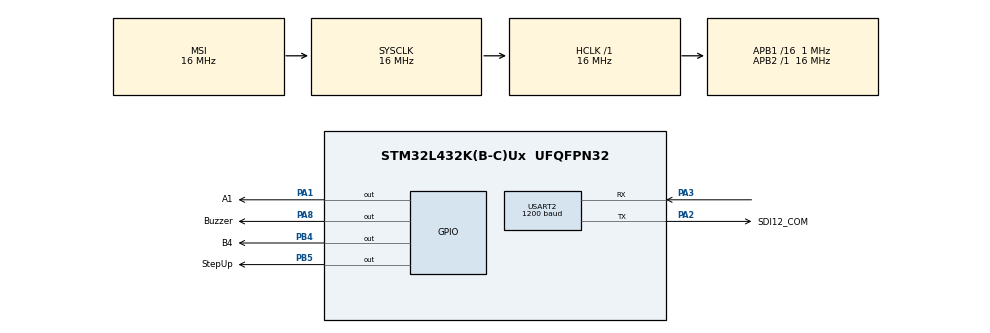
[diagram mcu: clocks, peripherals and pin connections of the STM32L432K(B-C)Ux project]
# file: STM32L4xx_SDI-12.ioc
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Mcu.Family=STM32L4
Mcu.Name=STM32L432K(B-C)Ux
Mcu.Package=UFQFPN32
NVIC.PriorityGroup=NVIC_PRIORITYGROUP_4
NVIC.RTC_WKUP_IRQn=true\:0\:0\:false\:false\:true\:true\:true\:true
PA1.GPIO_Label=A1
PA1.Signal=GPIO_Output
PA13\ (JTMS-SWDIO).Mode=Trace_Asynchronous_SW
PA13\ (JTMS-SWDIO).Signal=SYS_JTMS-SWDIO
PA14\ (JTCK-SWCLK).Mode=Trace_Asynchronous_SW
PA14\ (JTCK-SWCLK).Signal=SYS_JTCK-SWCLK
PA2.GPIO_Label=SDI12_COM
PA2.Mode=Asynchronous
PA2.Signal=USART2_TX
PA3.Mode=Asynchronous
PA3.Signal=USART2_RX
PA8.GPIO_Label=Buzzer
PA8.Signal=GPIO_Output
PB3\ (JTDO-TRACESWO).Mode=Trace_Asynchronous_SW
PB3\ (JTDO-TRACESWO).Signal=SYS_JTDO-SWO
PB4\ (NJTRST).GPIO_Label=B4
PB4\ (NJTRST).Signal=GPIO_Output
PB5.GPIO_Label=StepUp
PB5.Signal=GPIO_Output
PC14-OSC32_IN\ (PC14).Mode=LSE-External-Oscillator
PC14-OSC32_IN\ (PC14).Signal=RCC_OSC32_IN
PC15-OSC32_OUT\ (PC15).Mode=LSE-External-Oscillator
PC15-OSC32_OUT\ (PC15).Signal=RCC_OSC32_OUT
ProjectManager.HeapSize=0x200
ProjectManager.StackSize=0x400
ProjectManager.TargetToolchain=STM32CubeIDE
RCC.ADCFreq_Value=64000000
RCC.AHBFreq_Value=16000000
RCC.APB1CLKDivider=RCC_HCLK_DIV16
RCC.APB1Freq_Value=1000000
RCC.APB1TimFreq_Value=2000000
RCC.APB2Freq_Value=16000000
RCC.APB2TimFreq_Value=16000000
RCC.CortexFreq_Value=16000000
RCC.HCLKFreq_Value=16000000
RCC.HSE_VALUE=8000000
RCC.HSI48_VALUE=48000000
RCC.HSI_VALUE=16000000
RCC.MSIClockRange=RCC_MSIRANGE_8
RCC.MSI_VALUE=16000000
RCC.PLLN=16
RCC.PLLSAI1Q=RCC_PLLQ_DIV4
RCC.RTCClockSelection=RCC_RTCCLKSOURCE_LSE
RCC.SYSCLKFreq_VALUE=16000000
RCC.USBFreq_Value=32000000
RCC.VCOOutputFreq_Value=256000000
RTC.WakeUpClock=RTC_WAKEUPCLOCK_CK_SPRE_16BITS
USART2.BaudRate=1200
USART2.Parity=PARITY_EVEN
USART2.RxPinLevelInvertParam=ADVFEATURE_RXINV_ENABLE
USART2.SwapParam=ADVFEATURE_SWAP_ENABLE
USART2.TxPinLevelInvertParam=ADVFEATURE_TXINV_ENABLE
USART2.VirtualMode-Asynchronous=VM_ASYNC
VP_RNG_VS_RNG.Mode=RNG_Activate
VP_RTC_VS_RTC_Activate.Mode=RTC_Enabled
VP_RTC_VS_RTC_Calendar.Mode=RTC_Calendar
VP_RTC_VS_RTC_WakeUp_intern.Mode=WakeUp
board=custom

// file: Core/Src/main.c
/* USER CODE BEGIN Header */
/**
  ******************************************************************************
  * @file           : main.c
  * @brief          : Main program body
  ******************************************************************************
  * @attention
  *
  * Copyright (c) 2023 STMicroelectronics.
  * All rights reserved.
  *
  * This software is licensed under terms that can be found in the LICENSE file
  * in the root directory of this software component.
  * If no LICENSE file comes with this software, it is provided AS-IS.
  *
  ******************************************************************************
  */
/* USER CODE END Header */
#include "main.h"

/* USER CODE BEGIN Includes */
#include "sdi12.h"
#include "sdi12_debug.h"
/* USER CODE END Includes */

RNG_HandleTypeDef hrng;
RTC_HandleTypeDef hrtc;
UART_HandleTypeDef huart2;

void SystemClock_Config(void);
static void MX_GPIO_Init(void);
static void MX_RNG_Init(void);
static void MX_RTC_Init(void);
static void MX_USART2_UART_Init(void);

int main(void)
{

  /* MCU Configuration--------------------------------------------------------*/

  /* Reset of all peripherals, Initializes the Flash interface and the Systick. */
  HAL_Init();

  /* Configure the system clock */
  SystemClock_Config();

  /* Initialize all configured peripherals */
  MX_GPIO_Init();
  MX_RNG_Init();
  MX_RTC_Init();
  MX_USART2_UART_Init();
  /* USER CODE BEGIN 2 */
  SDI12_Init(&huart2);
  HAL_GPIO_WritePin(StepUp_GPIO_Port, StepUp_Pin, SET);
  HAL_GPIO_WritePin(B4_GPIO_Port, B4_Pin, SET);
  HAL_GPIO_WritePin(A1_GPIO_Port, A1_Pin, SET);
  char data[100];
  char addr = '0';
  SDI12_Measure_TypeDef measurement_info;
  /* USER CODE END 2 */

  /* Infinite loop */
  while (1)
  {

    /* USER CODE BEGIN 3 */
	memset(data, 0, sizeof(data));
	SDI12_StartMeasurement(addr, &measurement_info);
	HAL_Delay(500);
	SDI12_SendData(addr, &measurement_info, data);
	HAL_Delay(3000);
  }
  /* USER CODE END 3 */
}

void SystemClock_Config(void)
{
  RCC_OscInitTypeDef RCC_OscInitStruct = {0};
  RCC_ClkInitTypeDef RCC_ClkInitStruct = {0};

  /** Configure the main internal regulator output voltage
  */
  if (HAL_PWREx_ControlVoltageScaling(PWR_REGULATOR_VOLTAGE_SCALE1) != HAL_OK)
  {
    Error_Handler();
  }

  /** Configure LSE Drive Capability
  */
  HAL_PWR_EnableBkUpAccess();
  __HAL_RCC_LSEDRIVE_CONFIG(RCC_LSEDRIVE_LOW);

  /** Initializes the RCC Oscillators according to the specified parameters
  * in the RCC_OscInitTypeDef structure.
  */
  RCC_OscInitStruct.OscillatorType = RCC_OSCILLATORTYPE_LSE|RCC_OSCILLATORTYPE_MSI;
  RCC_OscInitStruct.LSEState = RCC_LSE_ON;
  RCC_OscInitStruct.MSIState = RCC_MSI_ON;
  RCC_OscInitStruct.MSICalibrationValue = 0;
  RCC_OscInitStruct.MSIClockRange = RCC_MSIRANGE_8;
  RCC_OscInitStruct.PLL.PLLState = RCC_PLL_NONE;
  if (HAL_RCC_OscConfig(&RCC_OscInitStruct) != HAL_OK)
  {
    Error_Handler();
  }

  /** Initializes the CPU, AHB and APB buses clocks
  */
  RCC_ClkInitStruct.ClockType = RCC_CLOCKTYPE_HCLK|RCC_CLOCKTYPE_SYSCLK
                              |RCC_CLOCKTYPE_PCLK1|RCC_CLOCKTYPE_PCLK2;
  RCC_ClkInitStruct.SYSCLKSource = RCC_SYSCLKSOURCE_MSI;
  RCC_ClkInitStruct.AHBCLKDivider = RCC_SYSCLK_DIV1;
  RCC_ClkInitStruct.APB1CLKDivider = RCC_HCLK_DIV16;
  RCC_ClkInitStruct.APB2CLKDivider = RCC_HCLK_DIV1;

  if (HAL_RCC_ClockConfig(&RCC_ClkInitStruct, FLASH_LATENCY_0) != HAL_OK)
  {
    Error_Handler();
  }

  /** Enable MSI Auto calibration
  */
  HAL_RCCEx_EnableMSIPLLMode();
}

static void MX_RNG_Init(void)
{

  hrng.Instance = RNG;
  if (HAL_RNG_Init(&hrng) != HAL_OK)
  {
    Error_Handler();
  }

}

static void MX_RTC_Init(void)
{

  RTC_TimeTypeDef sTime = {0};
  RTC_DateTypeDef sDate = {0};

  /** Initialize RTC Only
  */
  hrtc.Instance = RTC;
  hrtc.Init.HourFormat = RTC_HOURFORMAT_24;
  hrtc.Init.AsynchPrediv = 127;
  hrtc.Init.SynchPrediv = 255;
  hrtc.Init.OutPut = RTC_OUTPUT_DISABLE;
  hrtc.Init.OutPutRemap = RTC_OUTPUT_REMAP_NONE;
  hrtc.Init.OutPutPolarity = RTC_OUTPUT_POLARITY_HIGH;
  hrtc.Init.OutPutType = RTC_OUTPUT_TYPE_OPENDRAIN;
  if (HAL_RTC_Init(&hrtc) != HAL_OK)
  {
    Error_Handler();
  }

  /** Initialize RTC and set the Time and Date
  */
  sTime.Hours = 0x0;
  sTime.Minutes = 0x0;
  sTime.Seconds = 0x0;
  sTime.DayLightSaving = RTC_DAYLIGHTSAVING_NONE;
  sTime.StoreOperation = RTC_STOREOPERATION_RESET;
  if (HAL_RTC_SetTime(&hrtc, &sTime, RTC_FORMAT_BCD) != HAL_OK)
  {
    Error_Handler();
  }
  sDate.WeekDay = RTC_WEEKDAY_MONDAY;
  sDate.Month = RTC_MONTH_JANUARY;
  sDate.Date = 0x1;
  sDate.Year = 0x0;

  if (HAL_RTC_SetDate(&hrtc, &sDate, RTC_FORMAT_BCD) != HAL_OK)
  {
    Error_Handler();
  }

}

static void MX_USART2_UART_Init(void)
{

  huart2.Instance = USART2;
  huart2.Init.BaudRate = 1200;
  huart2.Init.WordLength = UART_WORDLENGTH_8B;
  huart2.Init.StopBits = UART_STOPBITS_1;
  huart2.Init.Parity = UART_PARITY_EVEN;
  huart2.Init.Mode = UART_MODE_TX_RX;
  huart2.Init.HwFlowCtl = UART_HWCONTROL_NONE;
  huart2.Init.OverSampling = UART_OVERSAMPLING_16;
  huart2.Init.OneBitSampling = UART_ONE_BIT_SAMPLE_DISABLE;
  huart2.AdvancedInit.AdvFeatureInit = UART_ADVFEATURE_TXINVERT_INIT|UART_ADVFEATURE_RXINVERT_INIT
                              |UART_ADVFEATURE_SWAP_INIT;
  huart2.AdvancedInit.TxPinLevelInvert = UART_ADVFEATURE_TXINV_ENABLE;
  huart2.AdvancedInit.RxPinLevelInvert = UART_ADVFEATURE_RXINV_ENABLE;
  huart2.AdvancedInit.Swap = UART_ADVFEATURE_SWAP_ENABLE;
  if (HAL_UART_Init(&huart2) != HAL_OK)
  {
    Error_Handler();
  }

}

static void MX_GPIO_Init(void)
{
  GPIO_InitTypeDef GPIO_InitStruct = {0};

  /* GPIO Ports Clock Enable */
  __HAL_RCC_GPIOC_CLK_ENABLE();
  __HAL_RCC_GPIOA_CLK_ENABLE();
  __HAL_RCC_GPIOB_CLK_ENABLE();

  /*Configure GPIO pin Output Level */
  HAL_GPIO_WritePin(GPIOA, A1_Pin|Buzzer_Pin, GPIO_PIN_RESET);

  /*Configure GPIO pin Output Level */
  HAL_GPIO_WritePin(GPIOB, B4_Pin|StepUp_Pin, GPIO_PIN_RESET);

  /*Configure GPIO pins : A1_Pin Buzzer_Pin */
  GPIO_InitStruct.Pin = A1_Pin|Buzzer_Pin;
  GPIO_InitStruct.Mode = GPIO_MODE_OUTPUT_PP;
  GPIO_InitStruct.Pull = GPIO_NOPULL;
  GPIO_InitStruct.Speed = GPIO_SPEED_FREQ_LOW;
  HAL_GPIO_Init(GPIOA, &GPIO_InitStruct);

  /*Configure GPIO pins : B4_Pin StepUp_Pin */
  GPIO_InitStruct.Pin = B4_Pin|StepUp_Pin;
  GPIO_InitStruct.Mode = GPIO_MODE_OUTPUT_PP;
  GPIO_InitStruct.Pull = GPIO_NOPULL;
  GPIO_InitStruct.Speed = GPIO_SPEED_FREQ_LOW;
  HAL_GPIO_Init(GPIOB, &GPIO_InitStruct);

}

void Error_Handler(void)
{
  __disable_irq();
  while (1)
  {
  }
}
